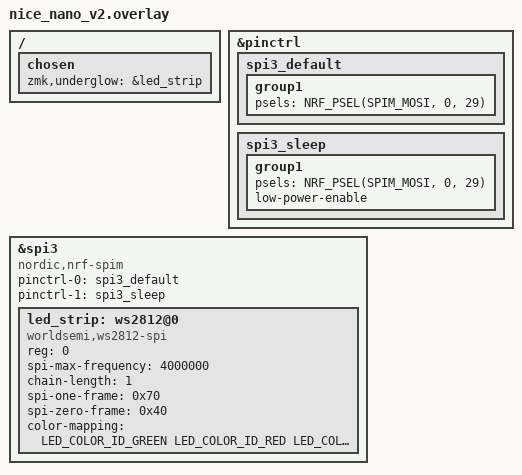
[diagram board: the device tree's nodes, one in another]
/**
 * Generated by Shield Wizard for ZMK
 * Applies to part "left" with controller "nice_nano_v2"
 */

// pin control for spi3
// - MOSI on D20
&pinctrl {
    /* configuration for spi3 device, default state */
    spi3_default: spi3_default {
        group1 {
            psels = <NRF_PSEL(SPIM_MOSI, 0, 29)>;
        };
    };
    /* configuration for spi3 device, sleep state */
    spi3_sleep: spi3_sleep {
        group1 {
            psels = <NRF_PSEL(SPIM_MOSI, 0, 29)>;
            low-power-enable;
        };
    };
};
&spi3 {
    compatible = "nordic,nrf-spim";
    status = "okay";
    pinctrl-0 = <&spi3_default>;
    pinctrl-1 = <&spi3_sleep>;
    pinctrl-names = "default", "sleep";
};

// devices on spi3

#include <dt-bindings/led/led.h>
&spi3 {
    led_strip: ws2812@0 {
        compatible = "worldsemi,ws2812-spi";
        reg = <0>;
        spi-max-frequency = <4000000>;

        chain-length = <1>;
        spi-one-frame = <0x70>;
        spi-zero-frame = <0x40>;
        color-mapping = <LED_COLOR_ID_GREEN
                         LED_COLOR_ID_RED
                         LED_COLOR_ID_BLUE>;
    };
};
/ {
    chosen {
        zmk,underglow = &led_strip;
    };
};
